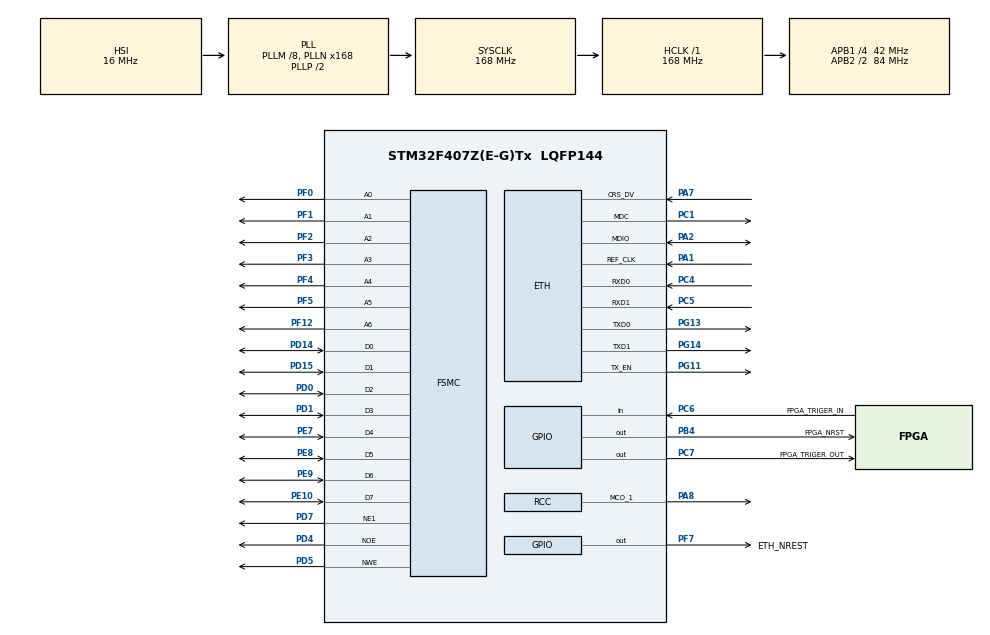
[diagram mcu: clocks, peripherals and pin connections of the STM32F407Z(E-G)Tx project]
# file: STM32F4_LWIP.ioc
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ETH.MediaInterface=HAL_ETH_RMII_MODE
FSMC.WriteOperation1=FSMC_WRITE_OPERATION_ENABLE
LWIP.IP_ADDRESS=192.168.002.019
LWIP.LWIP_DHCP=0
LWIP.LWIP_UDP=0
LWIP.NETMASK_ADDRESS=255.255.255.000
LWIP.Version=v2.1.2_Cube
Mcu.Family=STM32F4
Mcu.Name=STM32F407Z(E-G)Tx
Mcu.Package=LQFP144
NVIC.ETH_IRQn=true\:0\:0\:false\:false\:true\:true\:true\:true
NVIC.PriorityGroup=NVIC_PRIORITYGROUP_4
NVIC.TIM7_IRQn=true\:15\:0\:false\:false\:true\:false\:true\:true
NVIC.TimeBase=TIM7_IRQn
NVIC.TimeBaseIP=TIM7
PA1.Mode=RMII
PA1.Signal=ETH_REF_CLK
PA13.Mode=Serial_Wire
PA13.Signal=SYS_JTMS-SWDIO
PA14.Mode=Serial_Wire
PA14.Signal=SYS_JTCK-SWCLK
PA2.Mode=RMII
PA2.Signal=ETH_MDIO
PA7.Mode=RMII
PA7.Signal=ETH_CRS_DV
PA8.GPIO_Speed=GPIO_SPEED_FREQ_VERY_HIGH
PA8.Mode=Clock-out-1
PA8.Signal=RCC_MCO_1
PB4.GPIO_Label=FPGA_NRST
PB4.Signal=GPIO_Output
PC1.Mode=RMII
PC1.Signal=ETH_MDC
PC4.Mode=RMII
PC4.Signal=ETH_RXD0
PC5.Mode=RMII
PC5.Signal=ETH_RXD1
PC6.GPIO_Label=FPGA_TRIGER_IN
PC6.Signal=GPIO_Input
PC7.GPIO_Label=FPGA_TRIGER_OUT
PC7.Signal=GPIO_Output
PD0.Signal=FSMC_D2_DA2
PD1.Signal=FSMC_D3_DA3
PD14.Signal=FSMC_D0_DA0
PD15.Signal=FSMC_D1_DA1
PD4.Signal=FSMC_NOE
PD5.Signal=FSMC_NWE
PD7.Mode=NorPsramChipSelect1_1
PD7.Signal=FSMC_NE1
PE10.Signal=FSMC_D7_DA7
PE7.Signal=FSMC_D4_DA4
PE8.Signal=FSMC_D5_DA5
PE9.Signal=FSMC_D6_DA6
PF0.Signal=FSMC_A0
PF1.Signal=FSMC_A1
PF12.Signal=FSMC_A6
PF2.Signal=FSMC_A2
PF3.Signal=FSMC_A3
PF4.Signal=FSMC_A4
PF5.Signal=FSMC_A5
PF7.GPIO_Label=ETH_NREST
PF7.GPIO_PuPd=GPIO_NOPULL
PF7.PinState=GPIO_PIN_SET
PF7.Signal=GPIO_Output
PG11.Mode=RMII
PG11.Signal=ETH_TX_EN
PG13.Mode=RMII
PG13.Signal=ETH_TXD0
PG14.Mode=RMII
PG14.Signal=ETH_TXD1
PH0-OSC_IN.Mode=HSE-External-Oscillator
PH0-OSC_IN.Signal=RCC_OSC_IN
PH1-OSC_OUT.Mode=HSE-External-Oscillator
PH1-OSC_OUT.Signal=RCC_OSC_OUT
ProjectManager.HeapSize=0x200
ProjectManager.StackSize=0x400
ProjectManager.TargetToolchain=MDK-ARM V5.32
RCC.48MHZClocksFreq_Value=84000000
RCC.AHBFreq_Value=168000000
RCC.APB1CLKDivider=RCC_HCLK_DIV4
RCC.APB1Freq_Value=42000000
RCC.APB1TimFreq_Value=84000000
RCC.APB2CLKDivider=RCC_HCLK_DIV2
RCC.APB2Freq_Value=84000000
RCC.APB2TimFreq_Value=168000000
RCC.CortexFreq_Value=168000000
RCC.HCLKFreq_Value=168000000
RCC.HSE_VALUE=25000000
RCC.HSI_VALUE=16000000
RCC.LSE_VALUE=32768
RCC.PLLM=8
RCC.PLLN=168
RCC.RCC_MCO1Source=RCC_MCO1SOURCE_HSE
RCC.SYSCLKFreq_VALUE=168000000
RCC.SYSCLKSource=RCC_SYSCLKSOURCE_PLLCLK
RCC.VCOOutputFreq_Value=336000000
SH.FSMC_A0.0=FSMC_A0,7b-a1
SH.FSMC_A1.0=FSMC_A1,7b-a1
SH.FSMC_A2.0=FSMC_A2,7b-a1
SH.FSMC_A3.0=FSMC_A3,7b-a1
SH.FSMC_A4.0=FSMC_A4,7b-a1
SH.FSMC_A5.0=FSMC_A5,7b-a1
SH.FSMC_A6.0=FSMC_A6,7b-a1
SH.FSMC_D0_DA0.0=FSMC_D0,8b-d1
SH.FSMC_D1_DA1.0=FSMC_D1,8b-d1
SH.FSMC_D2_DA2.0=FSMC_D2,8b-d1
SH.FSMC_D3_DA3.0=FSMC_D3,8b-d1
SH.FSMC_D4_DA4.0=FSMC_D4,8b-d1
SH.FSMC_D5_DA5.0=FSMC_D5,8b-d1
SH.FSMC_D6_DA6.0=FSMC_D6,8b-d1
SH.FSMC_D7_DA7.0=FSMC_D7,8b-d1
SH.FSMC_NOE.0=FSMC_NOE,Sram1
SH.FSMC_NWE.0=FSMC_NWE,Sram1
VP_CRC_VS_CRC.Mode=CRC_Activate
VP_LWIP_VS_Enabled.Mode=Enabled
VP_SYS_VS_tim7.Mode=TIM7
board=custom

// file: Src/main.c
/* USER CODE BEGIN Header */
/**
  ******************************************************************************
  * @file           : main.c
  * @brief          : Main program body
  ******************************************************************************
  * @attention
  *
  * Copyright (c) 2025 STMicroelectronics.
  * All rights reserved.
  *
  * This software is licensed under terms that can be found in the LICENSE file
  * in the root directory of this software component.
  * If no LICENSE file comes with this software, it is provided AS-IS.
  *
  ******************************************************************************
  */
/* USER CODE END Header */
#include "main.h"
#include "crc.h"
#include "lwip.h"
#include "gpio.h"
#include "fsmc.h"

/* USER CODE BEGIN Includes */
#include "UserFSMC.h"
/* USER CODE END Includes */

void SystemClock_Config(void);

int main(void)
{

  /* USER CODE BEGIN 1 */
	uint8_t w_temp[2] = {0x01, 0x02};
	uint8_t r_temp[2];
  /* USER CODE END 1 */

  /* MCU Configuration--------------------------------------------------------*/

  /* Reset of all peripherals, Initializes the Flash interface and the Systick. */
  HAL_Init();

  /* Configure the system clock */
  SystemClock_Config();

  /* Initialize all configured peripherals */
  MX_GPIO_Init();
  MX_LWIP_Init();
  MX_FSMC_Init();
  MX_CRC_Init();
  /* USER CODE BEGIN 2 */
  User_InitModule(); // Initialize FSMC Module
//  User_EnableModule(0x01); // Enable Module 1
//  User_EnableModule(0x02); // Enable Module 2
//  User_SetPulseWidth(6000);  // Set Pulse Width to 6000ns

	User_FSMC_Test();
  /* USER CODE END 2 */

  /* Infinite loop */
  while (1)
  {
    MX_LWIP_Process();
  }
}

void SystemClock_Config(void)
{
  RCC_OscInitTypeDef RCC_OscInitStruct = {0};
  RCC_ClkInitTypeDef RCC_ClkInitStruct = {0};

  /** Configure the main internal regulator output voltage
  */
  __HAL_RCC_PWR_CLK_ENABLE();
  __HAL_PWR_VOLTAGESCALING_CONFIG(PWR_REGULATOR_VOLTAGE_SCALE1);

  /** Initializes the RCC Oscillators according to the specified parameters
  * in the RCC_OscInitTypeDef structure.
  */
  RCC_OscInitStruct.OscillatorType = RCC_OSCILLATORTYPE_HSI|RCC_OSCILLATORTYPE_HSE;
  RCC_OscInitStruct.HSEState = RCC_HSE_ON;
  RCC_OscInitStruct.HSIState = RCC_HSI_ON;
  RCC_OscInitStruct.HSICalibrationValue = RCC_HSICALIBRATION_DEFAULT;
  RCC_OscInitStruct.PLL.PLLState = RCC_PLL_ON;
  RCC_OscInitStruct.PLL.PLLSource = RCC_PLLSOURCE_HSI;
  RCC_OscInitStruct.PLL.PLLM = 8;
  RCC_OscInitStruct.PLL.PLLN = 168;
  RCC_OscInitStruct.PLL.PLLP = RCC_PLLP_DIV2;
  RCC_OscInitStruct.PLL.PLLQ = 4;
  if (HAL_RCC_OscConfig(&RCC_OscInitStruct) != HAL_OK)
  {
    Error_Handler();
  }

  /** Initializes the CPU, AHB and APB buses clocks
  */
  RCC_ClkInitStruct.ClockType = RCC_CLOCKTYPE_HCLK|RCC_CLOCKTYPE_SYSCLK
                              |RCC_CLOCKTYPE_PCLK1|RCC_CLOCKTYPE_PCLK2;
  RCC_ClkInitStruct.SYSCLKSource = RCC_SYSCLKSOURCE_PLLCLK;
  RCC_ClkInitStruct.AHBCLKDivider = RCC_SYSCLK_DIV1;
  RCC_ClkInitStruct.APB1CLKDivider = RCC_HCLK_DIV4;
  RCC_ClkInitStruct.APB2CLKDivider = RCC_HCLK_DIV2;

  if (HAL_RCC_ClockConfig(&RCC_ClkInitStruct, FLASH_LATENCY_5) != HAL_OK)
  {
    Error_Handler();
  }
  HAL_RCC_MCOConfig(RCC_MCO1, RCC_MCO1SOURCE_HSE, RCC_MCODIV_1);
}

void HAL_TIM_PeriodElapsedCallback(TIM_HandleTypeDef *htim)
{
  if (htim->Instance == TIM7)
  {
    HAL_IncTick();
  }
}

void Error_Handler(void)
{
  __disable_irq();
  while (1)
  {
  }
}
